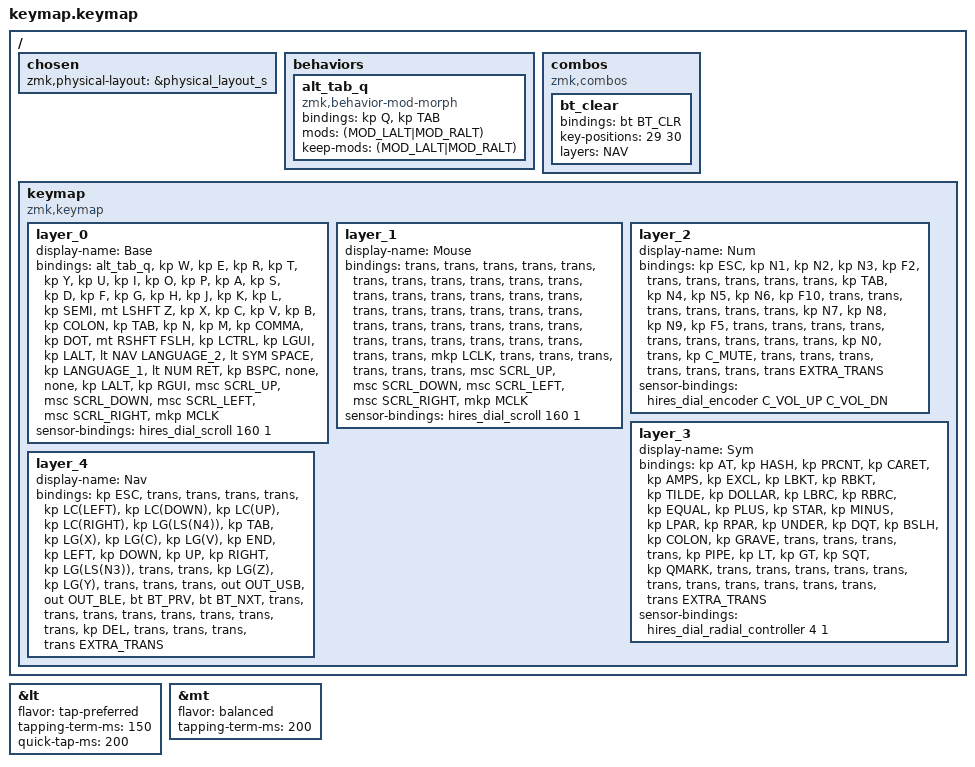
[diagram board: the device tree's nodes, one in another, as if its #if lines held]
#include <behaviors.dtsi>
#include <dt-bindings/zmk/bt.h>
#include <dt-bindings/zmk/keys.h>
#include <dt-bindings/zmk/outputs.h>
#include <dt-bindings/zmk/pointing.h>

#if defined(TORABO_TSUKI_LP_INPUT_HIRES_DIAL)
#include <behaviors/hires_dial.dtsi>
#endif

#define BASE   0
#define MOUSE  1
#define NUM    2
#define SYM    3
#define NAV    4

/* Decide hold by time only, with a shorter tapping-term than the default 200ms. */
&lt {
    flavor = "tap-preferred";
    tapping-term-ms = <150>;
    /* Re-pressing within 200ms after a tap is always a tap (fast repeated Space for IME conversion). */
    quick-tap-ms = <200>;
};

/* Z and / : tap for the character, hold for Shift. Shift only when another key is pressed and released while held. */
&mt {
    flavor = "balanced";
    tapping-term-ms = <200>;
};

#if defined(TORABO_TSUKI_LP_KSCAN_4_DIRECTION_SWITCH)
#define EXTRA_TRANS &trans &trans &trans &trans &trans
#elif defined(TORABO_TSUKI_LP_INPUT_HIRES_DIAL)
#define EXTRA_TRANS &trans
#else
#define EXTRA_TRANS
#endif

/ {
    chosen {
        zmk,physical-layout = &physical_layout_s;
    };

    behaviors {
        /* Q sends Tab while Alt is held, so Alt+Q works as Alt+Tab (hold Alt, tap Q repeatedly). */
        alt_tab_q: alt_tab_q {
            compatible = "zmk,behavior-mod-morph";
            #binding-cells = <0>;
            bindings = <&kp Q>, <&kp TAB>;
            mods = <(MOD_LALT|MOD_RALT)>;
            keep-mods = <(MOD_LALT|MOD_RALT)>;
        };
    };

    combos {
        compatible = "zmk,combos";

        /* BT_PRV + BT_NXT on the NAV layer */
        bt_clear {
            bindings = <&bt BT_CLR>;
            key-positions = <29 30>;
            layers = <NAV>;
        };
    };

    keymap {
        compatible = "zmk,keymap";

        layer_0 {
            display-name = "Base";
            bindings = <
&alt_tab_q &kp W     &kp E      &kp R              &kp T                                                            &kp Y        &kp U     &kp I      &kp O     &kp P
&kp A      &kp S     &kp D      &kp F              &kp G                                                            &kp H        &kp J     &kp K      &kp L     &kp SEMI
&mt LSHFT Z  &kp X   &kp C      &kp V              &kp B              &kp COLON                    &kp TAB          &kp N        &kp M     &kp COMMA  &kp DOT   &mt RSHFT FSLH
&kp LCTRL  &kp LGUI  &kp LALT   &lt NAV LANGUAGE_2  &lt SYM SPACE      &kp LANGUAGE_1               &lt NUM RET      &kp BSPC     &none     &none      &kp LALT  &kp RGUI
#if defined(TORABO_TSUKI_LP_KSCAN_4_DIRECTION_SWITCH)
&msc SCRL_UP &msc SCRL_DOWN &msc SCRL_LEFT &msc SCRL_RIGHT &mkp MCLK
#elif defined(TORABO_TSUKI_LP_INPUT_HIRES_DIAL)
&mkp MCLK
#endif
            >;
        };

        layer_1 {
            display-name = "Mouse";
            bindings = <
&trans  &trans  &trans  &trans  &trans                      &trans  &trans  &trans  &trans  &trans
&trans  &trans  &trans  &trans  &trans                      &trans  &trans  &trans  &trans  &trans
&trans  &trans  &trans  &trans  &trans  &trans      &trans  &trans  &trans  &trans  &trans  &trans
&trans  &trans  &trans  &trans  &trans  &mkp LCLK   &trans  &trans  &trans  &trans  &trans  &trans
#if defined(TORABO_TSUKI_LP_KSCAN_4_DIRECTION_SWITCH)
&msc SCRL_UP &msc SCRL_DOWN &msc SCRL_LEFT &msc SCRL_RIGHT &mkp MCLK
#elif defined(TORABO_TSUKI_LP_INPUT_HIRES_DIAL)
&mkp MCLK
#endif
            >;
        };

        /* Right thumb layer: keys are on the left hand. */
        layer_2 {
            display-name = "Num";
            bindings = <
&kp ESC  &kp N1  &kp N2  &kp N3  &kp F2                                &trans  &trans  &trans  &trans  &trans
&kp TAB  &kp N4  &kp N5  &kp N6  &kp F10                               &trans  &trans  &trans  &trans  &trans
&trans   &kp N7  &kp N8  &kp N9  &kp F5      &trans            &trans  &trans  &trans  &trans  &trans  &trans
&trans   &trans  &kp N0  &trans  &kp C_MUTE  &trans            &trans  &trans  &trans  &trans  &trans  &trans
EXTRA_TRANS
            >;
        };

        /* Left thumb layer: frequently used symbols are on the right hand. */
        layer_3 {
            display-name = "Sym";
            bindings = <
&kp AT    &kp HASH   &kp PRCNT  &kp CARET  &kp AMPS                         &kp EXCL   &kp LBKT  &kp RBKT  &kp TILDE  &kp DOLLAR
&kp LBRC  &kp RBRC   &kp EQUAL  &kp PLUS   &kp STAR                         &kp MINUS  &kp LPAR  &kp RPAR  &kp UNDER  &kp DQT
&kp BSLH  &kp COLON  &kp GRAVE  &trans     &trans    &trans         &trans  &kp PIPE   &kp LT    &kp GT    &kp SQT    &kp QMARK
&trans    &trans     &trans     &trans     &trans    &trans         &trans  &trans     &trans    &trans    &trans     &trans
EXTRA_TRANS
            >;
        };

        /* Left thumb layer: navigation, screenshots and Bluetooth are on the right hand. */
        layer_4 {
            display-name = "Nav";
            bindings = <
&kp ESC    &trans     &trans     &trans     &trans                         &kp LC(LEFT)  &kp LC(DOWN)  &kp LC(UP)    &kp LC(RIGHT)  &kp LG(LS(N4))
&kp TAB    &kp LG(X)  &kp LG(C)  &kp LG(V)  &kp END                        &kp LEFT      &kp DOWN      &kp UP        &kp RIGHT      &kp LG(LS(N3))
&trans     &trans     &kp LG(Z)  &kp LG(Y)  &trans   &trans        &trans  &out OUT_USB  &out OUT_BLE  &bt BT_PRV    &bt BT_NXT     &trans
&trans     &trans     &trans     &trans     &trans   &trans        &trans  &kp DEL       &trans        &trans        &trans         &trans
EXTRA_TRANS
            >;
        };
    };
};

#if defined(TORABO_TSUKI_LP_INPUT_HIRES_DIAL)
&{/keymap/layer_0} {
    sensor-bindings = <&hires_dial_scroll 160 1>;
};

&{/keymap/layer_1} {
    sensor-bindings = <&hires_dial_scroll 160 1>;
};

&{/keymap/layer_2} {
    sensor-bindings = <&hires_dial_encoder C_VOL_UP C_VOL_DN>;
};

&{/keymap/layer_3} {
    /* Quarter-speed Radial Controller motion: output/input = 1/4. */
    sensor-bindings = <&hires_dial_radial_controller 4 1>;
};
#endif
